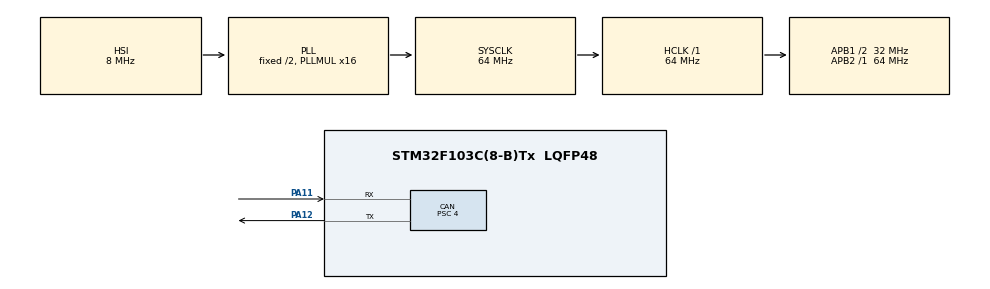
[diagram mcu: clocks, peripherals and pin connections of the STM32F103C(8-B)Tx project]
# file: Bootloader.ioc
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CAN.BS1=CAN_BS1_13TQ
CAN.BS2=CAN_BS2_2TQ
CAN.CalculateBaudRate=500000
CAN.CalculateTimeBit=2000
CAN.CalculateTimeQuantum=125.0
CAN.Prescaler=4
CAN.SJW=CAN_SJW_1TQ
Mcu.Family=STM32F1
Mcu.Name=STM32F103C(8-B)Tx
Mcu.Package=LQFP48
NVIC.PriorityGroup=NVIC_PRIORITYGROUP_4
NVIC.TIM1_UP_IRQn=true\:15\:0\:false\:false\:true\:false\:true\:true
NVIC.TimeBase=TIM1_UP_IRQn
NVIC.TimeBaseIP=TIM1
NVIC.USB_HP_CAN1_TX_IRQn=true\:7\:0\:true\:false\:true\:true\:true\:true
NVIC.USB_LP_CAN1_RX0_IRQn=true\:7\:0\:true\:false\:true\:true\:true\:true
PA11.Mode=CAN_Activate
PA11.Signal=CAN_RX
PA12.Mode=CAN_Activate
PA12.Signal=CAN_TX
PA13.Mode=Serial_Wire
PA13.Signal=SYS_JTMS-SWDIO
PA14.Mode=Serial_Wire
PA14.Signal=SYS_JTCK-SWCLK
ProjectManager.HeapSize=0x200
ProjectManager.StackSize=0x400
ProjectManager.TargetToolchain=STM32CubeIDE
RCC.AHBFreq_Value=64000000
RCC.APB1CLKDivider=RCC_HCLK_DIV2
RCC.APB1Freq_Value=32000000
RCC.APB1TimFreq_Value=64000000
RCC.APB2Freq_Value=64000000
RCC.APB2TimFreq_Value=64000000
RCC.HCLKFreq_Value=64000000
RCC.PLLMUL=RCC_PLL_MUL16
RCC.SYSCLKFreq_VALUE=64000000
RCC.SYSCLKSource=RCC_SYSCLKSOURCE_PLLCLK
RCC.USBFreq_Value=64000000
VP_SYS_VS_tim1.Mode=TIM1
board=custom

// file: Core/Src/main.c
/* USER CODE BEGIN Header */
/**
  ******************************************************************************
  * @file           : main.c
  * @brief          : Main program body
  ******************************************************************************
  * @attention
  *
  * Copyright (c) 2025 STMicroelectronics.
  * All rights reserved.
  *
  * This software is licensed under terms that can be found in the LICENSE file
  * in the root directory of this software component.
  * If no LICENSE file comes with this software, it is provided AS-IS.
  *
  ******************************************************************************
  */
/* USER CODE END Header */
#include "main.h"

/* USER CODE BEGIN Includes */
#include "Bootloader.h"
/* USER CODE END Includes */

CAN_HandleTypeDef hcan;

/* USER CODE BEGIN PV */

metadata_t MetaData;

/* USER CODE END PV */

void SystemClock_Config(void);
static void MX_GPIO_Init(void);
static void MX_CAN_Init(void);
/* USER CODE BEGIN PFP */

void CAN_Filter_Config(void);

/* USER CODE END PFP */

int main(void)
{

  /* USER CODE BEGIN 1 */

	uint32_t App;

  /* USER CODE END 1 */

  /* MCU Configuration--------------------------------------------------------*/

  /* Reset of all peripherals, Initializes the Flash interface and the Systick. */
  HAL_Init();

  /* Configure the system clock */
  SystemClock_Config();

  /* Initialize all configured peripherals */
  MX_GPIO_Init();
  MX_CAN_Init();
  /* USER CODE BEGIN 2 */

  /* Configure CAN filters to accept IDs */
  CAN_Filter_Config();

  /* Start CAN peripheral */
  if (HAL_CAN_Start(&hcan) != HAL_OK)
  {
    Error_Handler();
  }

  /* Enable RX FIFO0 message pending interrupt */
  if (HAL_CAN_ActivateNotification(&hcan, CAN_IT_RX_FIFO0_MSG_PENDING) != HAL_OK)
  {
    Error_Handler();
  }

  /* Read metadata from flash */
  ReadMetadata();

  if (MetaData.pending == 1U)
  {
      StartFirmwareReception();
  }
  else
  {
	  if (MetaData.active_app == 1U)
	  {
		  App = FLASH_APP1_START;
		  JumpToApp(App);
	  }
	  else if (MetaData.active_app == 2U)
	  {
		  App = FLASH_APP2_START;
		  JumpToApp(App);
	  }
  }

  /* USER CODE END 2 */

  /* Infinite loop */
  while (1)
  {

  }
}

void SystemClock_Config(void)
{
  RCC_OscInitTypeDef RCC_OscInitStruct = {0};
  RCC_ClkInitTypeDef RCC_ClkInitStruct = {0};

  /** Initializes the RCC Oscillators according to the specified parameters
  * in the RCC_OscInitTypeDef structure.
  */
  RCC_OscInitStruct.OscillatorType = RCC_OSCILLATORTYPE_HSI;
  RCC_OscInitStruct.HSIState = RCC_HSI_ON;
  RCC_OscInitStruct.HSICalibrationValue = RCC_HSICALIBRATION_DEFAULT;
  RCC_OscInitStruct.PLL.PLLState = RCC_PLL_ON;
  RCC_OscInitStruct.PLL.PLLSource = RCC_PLLSOURCE_HSI_DIV2;
  RCC_OscInitStruct.PLL.PLLMUL = RCC_PLL_MUL16;
  if (HAL_RCC_OscConfig(&RCC_OscInitStruct) != HAL_OK)
  {
    Error_Handler();
  }

  /** Initializes the CPU, AHB and APB buses clocks
  */
  RCC_ClkInitStruct.ClockType = RCC_CLOCKTYPE_HCLK|RCC_CLOCKTYPE_SYSCLK
                              |RCC_CLOCKTYPE_PCLK1|RCC_CLOCKTYPE_PCLK2;
  RCC_ClkInitStruct.SYSCLKSource = RCC_SYSCLKSOURCE_PLLCLK;
  RCC_ClkInitStruct.AHBCLKDivider = RCC_SYSCLK_DIV1;
  RCC_ClkInitStruct.APB1CLKDivider = RCC_HCLK_DIV2;
  RCC_ClkInitStruct.APB2CLKDivider = RCC_HCLK_DIV1;

  if (HAL_RCC_ClockConfig(&RCC_ClkInitStruct, FLASH_LATENCY_2) != HAL_OK)
  {
    Error_Handler();
  }
}

static void MX_CAN_Init(void)
{

  hcan.Instance = CAN1;
  hcan.Init.Prescaler = 4;
  hcan.Init.Mode = CAN_MODE_NORMAL;
  hcan.Init.SyncJumpWidth = CAN_SJW_1TQ;
  hcan.Init.TimeSeg1 = CAN_BS1_13TQ;
  hcan.Init.TimeSeg2 = CAN_BS2_2TQ;
  hcan.Init.TimeTriggeredMode = DISABLE;
  hcan.Init.AutoBusOff = DISABLE;
  hcan.Init.AutoWakeUp = DISABLE;
  hcan.Init.AutoRetransmission = DISABLE;
  hcan.Init.ReceiveFifoLocked = DISABLE;
  hcan.Init.TransmitFifoPriority = DISABLE;
  if (HAL_CAN_Init(&hcan) != HAL_OK)
  {
    Error_Handler();
  }

}

static void MX_GPIO_Init(void)
{

  /* GPIO Ports Clock Enable */
  __HAL_RCC_GPIOA_CLK_ENABLE();

}

/* USER CODE BEGIN 4 */

/**
  * @brief  Configures the CAN filter to receive only specific IDs
  */
void CAN_Filter_Config(void)
{
  /* Filter configuration for ID UPDATE_FRAME_ID */
  CAN_FilterTypeDef sFilterConfig0 = {0};
  sFilterConfig0.FilterBank = 0;
  sFilterConfig0.FilterMode = CAN_FILTERMODE_IDMASK;
  sFilterConfig0.FilterScale = CAN_FILTERSCALE_32BIT;
  sFilterConfig0.FilterIdHigh = (UPDATE_FRAME_ID << 5);
  sFilterConfig0.FilterIdLow = 0x0000;
  sFilterConfig0.FilterMaskIdHigh = 0xFFFF;  /* Match all bits of ID */
  sFilterConfig0.FilterMaskIdLow = 0x0000;
  sFilterConfig0.FilterFIFOAssignment = CAN_FILTER_FIFO0;
  sFilterConfig0.FilterActivation = ENABLE;
  sFilterConfig0.SlaveStartFilterBank = 14;

  if (HAL_CAN_ConfigFilter(&hcan, &sFilterConfig0) != HAL_OK)
  {
    Error_Handler();
  }

  /* Filter configuration for ID UPDATE_ACK_ID */
  CAN_FilterTypeDef sFilterConfig1 = {0};
  sFilterConfig1.FilterBank = 1;
  sFilterConfig1.FilterMode = CAN_FILTERMODE_IDMASK;
  sFilterConfig1.FilterScale = CAN_FILTERSCALE_32BIT;
  sFilterConfig1.FilterIdHigh = (UPDATE_ACK_ID << 5);
  sFilterConfig1.FilterIdLow = 0x0000;
  sFilterConfig1.FilterMaskIdHigh = 0xFFFF;  /* Match all bits of ID */
  sFilterConfig1.FilterMaskIdLow = 0x0000;
  sFilterConfig1.FilterFIFOAssignment = CAN_FILTER_FIFO0;
  sFilterConfig1.FilterActivation = ENABLE;
  sFilterConfig1.SlaveStartFilterBank = 14;

  if (HAL_CAN_ConfigFilter(&hcan, &sFilterConfig1) != HAL_OK)
  {
    Error_Handler();
  }
}

/* USER CODE END 4 */

void HAL_TIM_PeriodElapsedCallback(TIM_HandleTypeDef *htim)
{
  if (htim->Instance == TIM1) {
    HAL_IncTick();
  }
}

void Error_Handler(void)
{
  __disable_irq();
  while (1)
  {
  }
}
